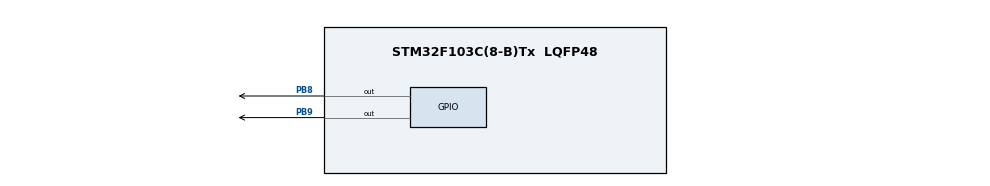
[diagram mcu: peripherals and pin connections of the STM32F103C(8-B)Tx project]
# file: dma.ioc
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Dma.MEMTOMEM.0.Direction=DMA_MEMORY_TO_MEMORY
Dma.MEMTOMEM.0.Instance=DMA1_Channel1
Dma.MEMTOMEM.0.MemDataAlignment=DMA_MDATAALIGN_BYTE
Dma.MEMTOMEM.0.MemInc=DMA_MINC_ENABLE
Dma.MEMTOMEM.0.Mode=DMA_NORMAL
Dma.MEMTOMEM.0.PeriphDataAlignment=DMA_PDATAALIGN_BYTE
Dma.MEMTOMEM.0.PeriphInc=DMA_PINC_ENABLE
Dma.MEMTOMEM.0.Priority=DMA_PRIORITY_LOW
Dma.Request0=MEMTOMEM
Mcu.Family=STM32F1
Mcu.Name=STM32F103C(8-B)Tx
Mcu.Package=LQFP48
NVIC.PriorityGroup=NVIC_PRIORITYGROUP_4
PA13.Mode=Serial_Wire
PA13.Signal=SYS_JTMS-SWDIO
PA14.Mode=Serial_Wire
PA14.Signal=SYS_JTCK-SWCLK
PB8.GPIO_ModeDefaultOutputPP=GPIO_MODE_OUTPUT_OD
PB8.GPIO_PuPd=GPIO_NOPULL
PB8.Signal=GPIO_Output
PB9.GPIO_ModeDefaultOutputPP=GPIO_MODE_OUTPUT_OD
PB9.GPIO_PuPd=GPIO_NOPULL
PB9.Signal=GPIO_Output
PD0-OSC_IN.Mode=HSE-External-Oscillator
PD0-OSC_IN.Signal=RCC_OSC_IN
PD1-OSC_OUT.Mode=HSE-External-Oscillator
PD1-OSC_OUT.Signal=RCC_OSC_OUT
ProjectManager.HeapSize=0x200
ProjectManager.StackSize=0x400
ProjectManager.TargetToolchain=STM32CubeIDE
RCC.APB1Freq_Value=8000000
RCC.APB2Freq_Value=8000000
board=custom

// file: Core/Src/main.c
/* USER CODE BEGIN Header */
/**
  ******************************************************************************
  * @file           : main.c
  * @brief          : Main program body
  ******************************************************************************
  * @attention
  *
  * Copyright (c) 2026 STMicroelectronics.
  * All rights reserved.
  *
  * This software is licensed under terms that can be found in the LICENSE file
  * in the root directory of this software component.
  * If no LICENSE file comes with this software, it is provided AS-IS.
  *
  ******************************************************************************
  */
/* USER CODE END Header */
#include "main.h"
#include "dma.h"
#include "gpio.h"

void SystemClock_Config(void);

int main(void)
{

  /* MCU Configuration--------------------------------------------------------*/

  /* Reset of all peripherals, Initializes the Flash interface and the Systick. */
  HAL_Init();

  /* Configure the system clock */
  SystemClock_Config();

  /* Initialize all configured peripherals */
  MX_GPIO_Init();
  MX_DMA_Init();

  /* Infinite loop */
  /* USER CODE BEGIN WHILE */
	OLED_Init();
	OLED_Clear();
	uint8_t DataA[] = {0x01, 0x02, 0x03, 0x04};
	uint8_t DataB[] = {0, 0, 0, 0};

	hdma_memtomem_dma1_channel1.Init.Mode = DMA_CIRCULAR;
	HAL_DMA_Init(&hdma_memtomem_dma1_channel1);
	HAL_DMA_Start(&hdma_memtomem_dma1_channel1, (uint32_t*)&DataA, (uint32_t)&DataB, 4);
  while (1)
  {
//		HAL_DMA_Start(&hdma_memtomem_dma1_channel1, (uint32_t*)&DataA, (uint32_t)&DataB, 4);
//		HAL_DMA_PollForTransfer(&hdma_memtomem_dma1_channel1, HAL_DMA_FULL_TRANSFER, HAL_MAX_DELAY);

		for(uint16_t i=0; i<4; i++)
		{
			DataA[i]++;
		}

		for(uint16_t i=0; i<4; i++)
		{
			OLED_ShowHexNum(1, 1+3*i, DataA[i], 2);
		}
		for(uint16_t j=0; j<4; j++)
		{
			OLED_ShowHexNum(3, 1+3*j, DataB[j], 2);
		}
		HAL_Delay(1000);
    /* USER CODE END WHILE */

  }
}

void SystemClock_Config(void)
{
  RCC_OscInitTypeDef RCC_OscInitStruct = {0};
  RCC_ClkInitTypeDef RCC_ClkInitStruct = {0};

  /** Initializes the RCC Oscillators according to the specified parameters
  * in the RCC_OscInitTypeDef structure.
  */
  RCC_OscInitStruct.OscillatorType = RCC_OSCILLATORTYPE_HSI;
  RCC_OscInitStruct.HSIState = RCC_HSI_ON;
  RCC_OscInitStruct.HSICalibrationValue = RCC_HSICALIBRATION_DEFAULT;
  RCC_OscInitStruct.PLL.PLLState = RCC_PLL_NONE;
  if (HAL_RCC_OscConfig(&RCC_OscInitStruct) != HAL_OK)
  {
    Error_Handler();
  }

  /** Initializes the CPU, AHB and APB buses clocks
  */
  RCC_ClkInitStruct.ClockType = RCC_CLOCKTYPE_HCLK|RCC_CLOCKTYPE_SYSCLK
                              |RCC_CLOCKTYPE_PCLK1|RCC_CLOCKTYPE_PCLK2;
  RCC_ClkInitStruct.SYSCLKSource = RCC_SYSCLKSOURCE_HSI;
  RCC_ClkInitStruct.AHBCLKDivider = RCC_SYSCLK_DIV1;
  RCC_ClkInitStruct.APB1CLKDivider = RCC_HCLK_DIV1;
  RCC_ClkInitStruct.APB2CLKDivider = RCC_HCLK_DIV1;

  if (HAL_RCC_ClockConfig(&RCC_ClkInitStruct, FLASH_LATENCY_0) != HAL_OK)
  {
    Error_Handler();
  }
}

void Error_Handler(void)
{
  __disable_irq();
  while (1)
  {
  }
}
